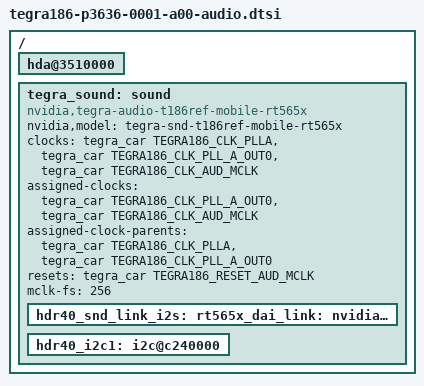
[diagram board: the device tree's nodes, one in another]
/*
 * Copyright (c) 2020, NVIDIA CORPORATION.  All rights reserved.
 *
 * This program is free software; you can redistribute it and/or modify it
 * under the terms and conditions of the GNU General Public License,
 * version 2, as published by the Free Software Foundation.
 *
 * This program is distributed in the hope it will be useful, but WITHOUT
 * ANY WARRANTY; without even the implied warranty of MERCHANTABILITY or
 * FITNESS FOR A PARTICULAR PURPOSE.  See the GNU General Public License for
 * more details.
 *
 * You should have received a copy of the GNU General Public License
 * along with this program.  If not, see <http://www.gnu.org/licenses/>.
 */

/*
 * T186 p3636-0001-a00 audio common DTSI file.
 */

#include <audio/tegra-platforms-audio-dai-links.dtsi>

/ {
	hda@3510000 {
		status = "okay";
	};

	tegra_sound: sound {
		status = "okay";
		compatible = "nvidia,tegra-audio-t186ref-mobile-rt565x";
		nvidia,model = "tegra-snd-t186ref-mobile-rt565x";
		clocks = <&tegra_car TEGRA186_CLK_PLLA>,
			 <&tegra_car TEGRA186_CLK_PLL_A_OUT0>,
			 <&tegra_car TEGRA186_CLK_AUD_MCLK>;
		clock-names = "pll_a", "pll_a_out0", "extern1";
		assigned-clocks = <&tegra_car TEGRA186_CLK_PLL_A_OUT0>,
				  <&tegra_car TEGRA186_CLK_AUD_MCLK>;
		assigned-clock-parents = <&tegra_car TEGRA186_CLK_PLLA>,
					 <&tegra_car TEGRA186_CLK_PLL_A_OUT0>;
		resets = <&tegra_car TEGRA186_RESET_AUD_MCLK>;
		reset-names = "extern1_rst";

		mclk-fs = <256>;

		/* TODO Avoid rt565x_dai_link definition by modifying common base file
		 * since current base does not have definition of dai link as
		 * rt565x_dai_link,  had to add here
		 */
		hdr40_snd_link_i2s: rt565x_dai_link: nvidia,dai-link-1 { };
		hdr40_i2c1: i2c@c240000 { };
	};
};
